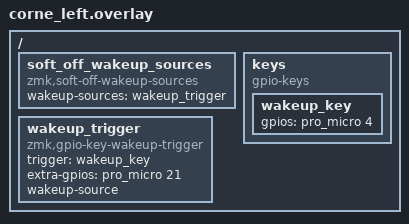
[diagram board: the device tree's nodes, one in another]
/ {
    soft_off_wakeup_sources {
        compatible = "zmk,soft-off-wakeup-sources";
        wakeup-sources = <&wakeup_trigger>;
    };

    keys {
        compatible = "gpio-keys";
        wakeup_key: wakeup_key {
            gpios = <&pro_micro 4 GPIO_ACTIVE_HIGH>;  // Row 0 for position 0 (TAB key)
        };
    };

    wakeup_trigger: wakeup_trigger {
        compatible = "zmk,gpio-key-wakeup-trigger";
        status = "okay";
        trigger = <&wakeup_key>;
        extra-gpios = <&pro_micro 21 GPIO_ACTIVE_HIGH>;  // Column 0
        wakeup-source;
    };
};
